# ARMv8MML register map
Vendor: ARM Ltd.; Series: ARMV8M; File version: 1.0
ARM 32-bit v8-M Baseline based device
CPU: CM4 r0p0, little endian, MPU, no FPU, 3 interrupt priority bits, 4 SAU regions
Registers are 32-bit, read-write, reset 0x0 unless marked. A register's access mark holds for its fields unless they carry their own. Offsets are from the block's base; lines under a group give offsets from that group; [hi:lo] are bit positions; {n}, {i} and the like mark numbered series; 'fields as' and 'values as' point back to an identical list; <NAME> marks a mode.

## Memory map
0xE000EDD0 SAU size 0x20 — Security Attribution Unit

## SAU — Security Attribution Unit
Base 0xE000EDD0
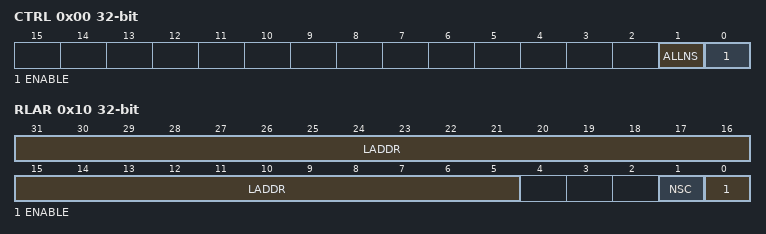
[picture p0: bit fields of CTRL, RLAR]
0x00 CTRL — Control Register
  [1] ALLNS — Security attribution if SAU disabled
    0=Secure (Memory is marked as secure); 1=Non_Secure (Memory is marked as non-secure)
  [0] ENABLE
    0=Disable (SAU is disabled); 1=Enable (SAU is enabled)
0x04 TYPE ro
  [7:0] SREGION — Number of implemented SAU regions
0x08 RNR — Region Number Register
  [7:0] REGION — Currently selected SAU region
    {v}=SAU_Region_{v} (Select SAU Region {v}) (v=0..3)
0x0C RBAR — Region Base Address Register
  [31:5] BADDR — Base Address
0x10 RLAR — Region Limit Address Register
  [31:5] LADDR — Limit Address
  [1] NSC — Non-Secure Callable
  [0] ENABLE — SAU Region enabled

## Licence text in the file
ARM Limited (ARM) is supplying this software for use with Cortex-M processor based microcontroller, but can be equally used for other suitable processor architectures. This file can be freely distributed. Modifications to this file shall be clearly marked. . THIS SOFTWARE IS PROVIDED "AS IS". NO WARRANTIES, WHETHER EXPRESS, IMPLIED. OR STATUTORY, INCLUDING, BUT NOT LIMITED TO, IMPLIED WARRANTIES OF. MERCHANTABILITY AND FITNESS FOR A PARTICULAR PURPOSE APPLY TO THIS SOFTWARE. ARM SHALL NOT, IN ANY CIRCUMSTANCES, BE LIABLE FOR SPECIAL, INCIDENTAL, OR. CONSEQUENTIAL DAMAGES, FOR ANY REASON WHATSOEVER.

## Notices in the file
Copyright (C) 2012-2014 ARM Limited. All rights reserved.
Purpose: System Viewer Description (SVD) Example (Schema Version 1.1)
This is a description of a none-existent and incomplete device
for demonstration purposes only.
Redistribution and use in source and binary forms, with or without
modification, are permitted provided that the following conditions are met:
- Redistributions of source code must retain the above copyright
notice, this list of conditions and the following disclaimer.
- Redistributions in binary form must reproduce the above copyright
notice, this list of conditions and the following disclaimer in the
documentation and/or other materials provided with the distribution.
- Neither the name of ARM nor the names of its contributors may be used
to endorse or promote products derived from this software without
specific prior written permission.
THIS SOFTWARE IS PROVIDED BY THE COPYRIGHT HOLDERS AND CONTRIBUTORS "AS IS"
AND ANY EXPRESS OR IMPLIED WARRANTIES, INCLUDING, BUT NOT LIMITED TO, THE
ARE DISCLAIMED. IN NO EVENT SHALL COPYRIGHT HOLDERS AND CONTRIBUTORS BE
LIABLE FOR ANY DIRECT, INDIRECT, INCIDENTAL, SPECIAL, EXEMPLARY, OR
CONSEQUENTIAL DAMAGES (INCLUDING, BUT NOT LIMITED TO, PROCUREMENT OF
SUBSTITUTE GOODS OR SERVICES; LOSS OF USE, DATA, OR PROFITS; OR BUSINESS
INTERRUPTION) HOWEVER CAUSED AND ON ANY THEORY OF LIABILITY, WHETHER IN
CONTRACT, STRICT LIABILITY, OR TORT (INCLUDING NEGLIGENCE OR OTHERWISE)
ARISING IN ANY WAY OUT OF THE USE OF THIS SOFTWARE, EVEN IF ADVISED OF THE
POSSIBILITY OF SUCH DAMAGE.
